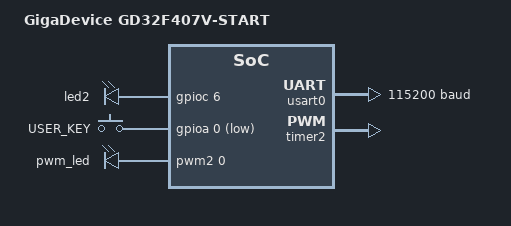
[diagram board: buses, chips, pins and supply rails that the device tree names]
/*
 * Copyright (c) 2022, TOKITA Hiroshi <tokita.hiroshi@gmail.com>
 * SPDX-License-Identifier: Apache-2.0
 */

/dts-v1/;

#include <gd/gd32f4xx/gd32f407xk.dtsi>
#include "gd32f407v_start-pinctrl.dtsi"
#include <zephyr/dt-bindings/input/input-event-codes.h>

/ {
	model = "GigaDevice GD32F407V-START";
	compatible = "gd,gd32f407v-start";

	chosen {
		zephyr,sram = &sram0;
		zephyr,flash = &flash0;
		zephyr,console = &usart0;
		zephyr,shell-uart = &usart0;
	};

	leds {
		compatible = "gpio-leds";
		led2: led2 {
			gpios = <&gpioc 6 GPIO_ACTIVE_HIGH>;
		};
	};

	gpio_keys {
		compatible = "gpio-keys";
		user_key: user_key {
			label = "USER_KEY";
			gpios = <&gpioa 0 GPIO_ACTIVE_LOW>;
			zephyr,code = <INPUT_KEY_0>;
		};
	};

	pwmleds {
		compatible = "pwm-leds";

		pwm_led: pwm_led {
			pwms = <&pwm2 0 PWM_MSEC(20) PWM_POLARITY_NORMAL>;
		};
	};

	aliases {
		led0 = &led2;
		sw0 = &user_key;
		pwm-led0 = &pwm_led;
	};
};

&gpioa {
	status = "okay";
};

&gpioc {
	status = "okay";
};

&usart0 {
	status = "okay";
	current-speed = <115200>;
	pinctrl-0 = <&usart0_default>;
	pinctrl-names = "default";
};

&timer2 {
	status = "okay";
	prescaler = <256>;

	pwm2: pwm {
		status = "okay";
		pinctrl-0 = <&pwm2_default>;
		pinctrl-names = "default";
	};
};
